VERSION ""

NS_ :

BS_:

BU_:

CM_ "FrameID: 0xC7";
BO_ 199 Toggle_Battery_Preconditioning: 8 Vector__XXX
 SG_ Battery_Preconditioning_0 : 24|8@1+ (1,0) [0|255] "" Vector__XXX
 SG_ Battery_Preconditioning_1 : 32|8@1+ (1,0) [0|255] "" Vector__XXX

CM_ "FrameID: 411";
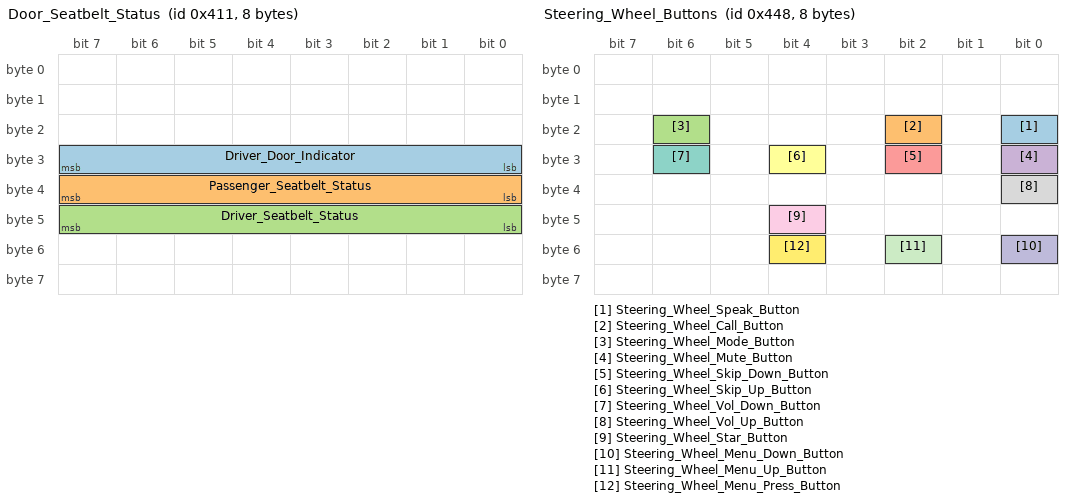
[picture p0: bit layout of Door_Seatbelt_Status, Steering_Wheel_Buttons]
BO_ 1041 Door_Seatbelt_Status: 8 Vector__XXX
 SG_ Driver_Door_Indicator      : 24|8@1+ (1,0) [0|255] "" Vector__XXX
 SG_ Passenger_Seatbelt_Status  : 32|8@1+ (1,0) [0|255] "" Vector__XXX
 SG_ Driver_Seatbelt_Status     : 40|8@1+ (1,0) [0|255] "" Vector__XXX

CM_ "FrameID: 412";
BO_ 1042 Brake_Pedal_Status: 8 Vector__XXX
 SG_ Brake_Pedal : 48|8@1+ (1,0) [0|255] "" Vector__XXX

CM_ "FrameID: 435";
BO_ 1077 Power_CAN_Status: 8 Vector__XXX
 SG_ Power_State : 56|8@1+ (1,0) [0|255] "" Vector__XXX

CM_ "FrameID: 0x2AD";
BO_ 685 BMS_Precond_Status: 8 Vector__XXX
 SG_ Battery_Precond_State : 8|8@1+ (1,0) [0|255] "" Vector__XXX

CM_ "FrameID: 0x418";
BO_ 1048 Steering_Wheel_Heating: 8 Vector__XXX
 SG_ Steering_Wheel_Heating_State : 16|8@1+ (1,0) [0|255] "" Vector__XXX

CM_ "FrameID: 0x438";
BO_ 1080 RearLeft_Seat_Heating: 8 Vector__XXX
 SG_ RearLeft_Seat_Heating_State :  0|8@1+ (1,0) [0|255] "" Vector__XXX

CM_ "FrameID: 0x448";
BO_ 1096 Steering_Wheel_Buttons: 8 Vector__XXX
 SG_ Steering_Wheel_Speak_Button      : 16|1@1+ (1,0) [0|1] "" Vector__XXX
 SG_ Steering_Wheel_Call_Button       : 18|1@1+ (1,0) [0|1] "" Vector__XXX
 SG_ Steering_Wheel_Mode_Button       : 22|1@1+ (1,0) [0|1] "" Vector__XXX
 SG_ Steering_Wheel_Mute_Button       : 24|1@1+ (1,0) [0|1] "" Vector__XXX
 SG_ Steering_Wheel_Skip_Down_Button  : 26|1@1+ (1,0) [0|1] "" Vector__XXX
 SG_ Steering_Wheel_Skip_Up_Button    : 28|1@1+ (1,0) [0|1] "" Vector__XXX
 SG_ Steering_Wheel_Vol_Down_Button   : 30|1@1+ (1,0) [0|1] "" Vector__XXX
 SG_ Steering_Wheel_Vol_Up_Button     : 32|1@1+ (1,0) [0|1] "" Vector__XXX
 SG_ Steering_Wheel_Star_Button       : 44|1@1+ (1,0) [0|1] "" Vector__XXX
 SG_ Steering_Wheel_Menu_Down_Button  : 48|1@1+ (1,0) [0|1] "" Vector__XXX
 SG_ Steering_Wheel_Menu_Up_Button    : 50|1@1+ (1,0) [0|1] "" Vector__XXX
 SG_ Steering_Wheel_Menu_Press_Button : 52|1@1+ (1,0) [0|1] "" Vector__XXX

CM_ "FrameID: 0x453";
BO_ 1107 RearRight_Seat_Heating: 8 Vector__XXX
 SG_ RearRight_Seat_Heating_State : 0|8@1+ (1,0) [0|255] "" Vector__XXX

CM_ "FrameID: 0x475";
BO_ 1141 Passenger_Seat_Heating: 8 Vector__XXX
 SG_ Passenger_Seat_Heating_State : 0|8@1+ (1,0) [0|255] "" Vector__XXX

CM_ "FrameID: 0x496";
BO_ 1174 Driver_Seat_Heating: 8 Vector__XXX
 SG_ Driver_Seat_Heating_State :    0|8@1+ (1,0) [0|255] "" Vector__XXX

CM_ "FrameID: 0x4ED";
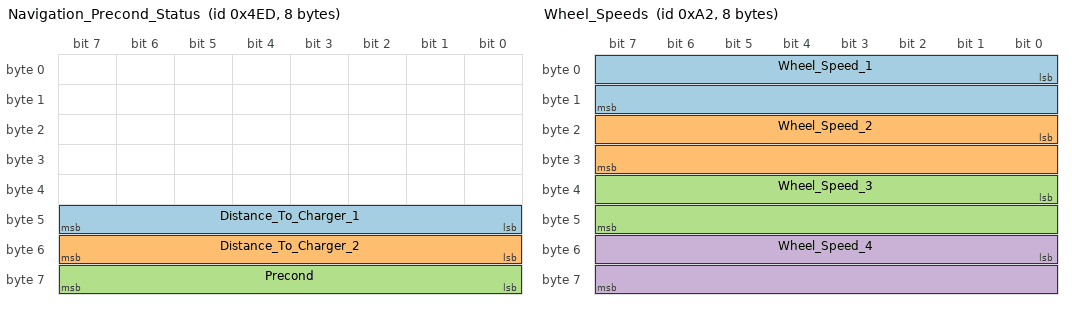
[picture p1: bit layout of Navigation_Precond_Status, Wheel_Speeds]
BO_ 1261 Navigation_Precond_Status: 8 Vector__XXX
 SG_ Distance_To_Charger_1 : 40|8@1+ (1,0) [0|255] "" Vector__XXX
 SG_ Distance_To_Charger_2 : 48|8@1+ (1,0) [0|255] "" Vector__XXX
 SG_ Precond               : 56|8@1+ (1,0) [0|255] "" Vector__XXX

CM_ "FrameID: 0x0A2";
BO_ 162 Wheel_Speeds: 8 Vector__XXX
 SG_ Wheel_Speed_1 : 0|16@1+  (0.03125,0) [0|2047.96] "kph" Vector__XXX
 SG_ Wheel_Speed_2 : 16|16@1+ (0.03125,0) [0|2047.96] "kph" Vector__XXX
 SG_ Wheel_Speed_3 : 32|16@1+ (0.03125,0) [0|2047.96] "kph" Vector__XXX
 SG_ Wheel_Speed_4 : 48|16@1+ (0.03125,0) [0|2047.96] "kph" Vector__XXX

CM_ "FrameID: 0x1AC";
BO_ 428 Cluster_Info: 8 Vector__XXX
 SG_ Speed_kph : 0|8@1+ (1,0) [0|255] "kph" Vector__XXX

CM_ "FrameID: 0x226";
CM_ "Probably wrong: unsigned int, and this byte doesn't change in my logs. --TRH"
BO_ 550 Ambient_Temperature: 8 Vector__XXX
 SG_ Outdoor_Temperature : 24|8@1+ (1,-40) [-40|215] "C" Vector__XXX

CM_ "FrameID: 0x227";
BO_ 551 Odometer: 8 Vector__XXX
 SG_ Odometer : 8|24@1+ (0.1,0) [0|1677721] "km" Vector__XXX

CM_ "FrameID: 0x2FC";
BO_ 764 Battery_Info: 8 Vector__XXX
 SG_ State_Of_Charge : 56|8@1+ (0.5,0) [0|100] "%" Vector__XXX

CM_ "FrameID: 0x31B";
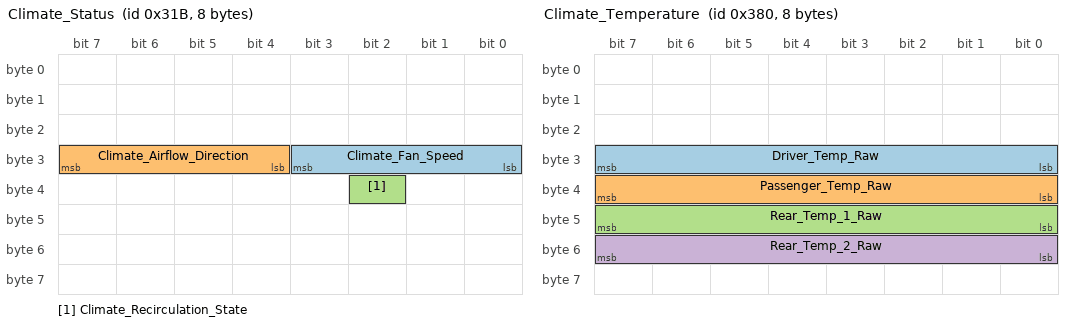
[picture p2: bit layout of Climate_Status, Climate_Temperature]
BO_ 795 Climate_Status: 8 Vector__XXX
 SG_ Climate_Fan_Speed          : 24|4@1+ (1,0) [0|15] "" Vector__XXX
 SG_ Climate_Airflow_Direction  : 28|4@1+ (1,0) [0|15] "" Vector__XXX
 SG_ Climate_Recirculation_State: 34|1@1+ (1,0) [0|1]  "" Vector__XXX

CM_ "FrameID: 0x380";
BO_ 896 Climate_Temperature: 8 Vector__XXX
 SG_ Driver_Temp_Raw    : 24|8@1+ (0.5,14) [14|32] "C" Vector__XXX
 SG_ Passenger_Temp_Raw : 32|8@1+ (0.5,14) [14|32] "C" Vector__XXX
 SG_ Rear_Temp_1_Raw    : 40|8@1+ (0.5,14) [14|32] "C" Vector__XXX
 SG_ Rear_Temp_2_Raw    : 48|8@1+ (0.5,14) [14|32] "C" Vector__XXX

CM_ "FrameID: 0x3AA";
BO_ 938 Charge_Port_Door: 8 Vector__XXX
 SG_ Port_Open : 33|1@1+ (1,0) [0|1] "" Vector__XXX

CM_ "FrameID: 0x414";
BO_ 1044 Trunk_Status: 8 Vector__XXX
 SG_ Trunk_Open : 24|1@1+ (1,0) [0|1] "" Vector__XXX

VAL_ 199  Battery_Preconditioning_0    64 "On" 0 "Off";
VAL_ 199  Battery_Preconditioning_1    3 "On" 0 "Off";
VAL_ 1041 Driver_Door_Indicator      51 "Open" 50 "Closed" 0 "Locked";
VAL_ 1041 Passenger_Seatbelt_Status  16 "Fastened" 0 "Unfastened";
VAL_ 1041 Driver_Seatbelt_Status      4 "Fastened" 0 "Unfastened";
VAL_ 1042 Brake_Pedal                 4 "Pressed" 0 "Not_Pressed";
VAL_ 1077 Power_State               255 "Car_Off" 0 "Car_on";
VAL_ 685  Battery_Precond_State        21 "On" 5 "Preparing" 1 "Off" ;
VAL_ 1080 RearLeft_Seat_Heating_State  65 "High" 49 "Low" 17 "Off" ;
VAL_ 1048 Steering_Wheel_Heating_State 1 "On" 0 "Off" ;
VAL_ 1096 Steering_Wheel_Speak_Button      1 "Pressed" 0 "Not_Pressed";
VAL_ 1096 Steering_Wheel_Call_Button       1 "Pressed" 0 "Not_Pressed";
VAL_ 1096 Steering_Wheel_Mode_Button       1 "Pressed" 0 "Not_Pressed";
VAL_ 1096 Steering_Wheel_Mute_Button       1 "Pressed" 0 "Not_Pressed";
VAL_ 1096 Steering_Wheel_Skip_Down_Button  1 "Pressed" 0 "Not_Pressed";
VAL_ 1096 Steering_Wheel_Skip_Up_Button    1 "Pressed" 0 "Not_Pressed";
VAL_ 1096 Steering_Wheel_Vol_Down_Button   1 "Pressed" 0 "Not_Pressed";
VAL_ 1096 Steering_Wheel_Vol_Up_Button     1 "Pressed" 0 "Not_Pressed";
VAL_ 1096 Steering_Wheel_Star_Button       1 "Pressed" 0 "Not_Pressed";
VAL_ 1096 Steering_Wheel_Menu_Down_Button  1 "Pressed" 0 "Not_Pressed";
VAL_ 1096 Steering_Wheel_Menu_Up_Button    1 "Pressed" 0 "Not_Pressed";
VAL_ 1096 Steering_Wheel_Menu_Press_Button 1 "Pressed" 0 "Not_Pressed";
VAL_ 1107 RearRight_Seat_Heating_State 65 "High" 49 "Low" 17 "Off" ;
VAL_ 1141 Passenger_Seat_Heating_State 70 "High" 62 "Medium" 54 "Low" 22 "Off" ;
VAL_ 1174 Driver_Seat_Heating_State    70 "High" 62 "Medium" 54 "Low" 22 "Off" ;
VAL_ 795 Climate_Fan_Speed 0 "Off" 2 "Speed_1" 3 "Speed_2" 4 "Speed_3" 5 "Speed_4" 6 "Speed_5" 7 "Speed_6" 8 "Speed_7" 9 "Speed_8" ;
VAL_ 795 Climate_Airflow_Direction 0 "Auto" 1 "Body" 2 "Body_Legs" 3 "Legs" 4 "Legs_Defog" ;
VAL_ 795 Climate_Recirculation_State 0 "Off" 1 "On" ;
VAL_ 896 Driver_Temp_Raw 0 "Off" ;
VAL_ 896 Passenger_Temp_Raw 0 "Off" ;
VAL_ 896 Rear_Temp_1_Raw 0 "Off" ;
VAL_ 896 Rear_Temp_2_Raw 0 "Off" ;

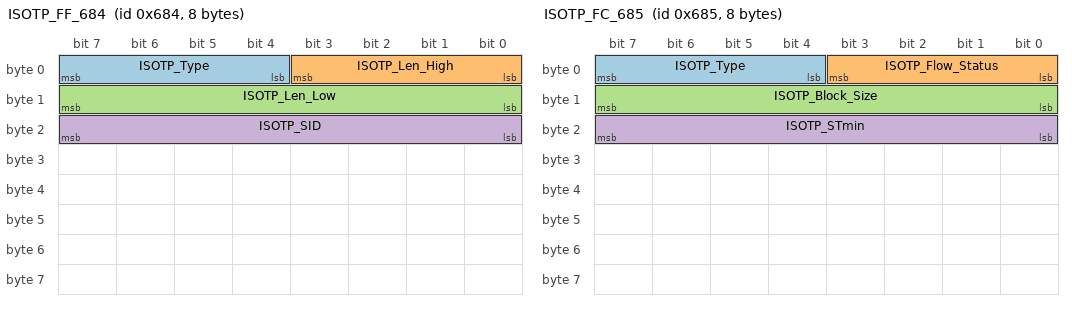
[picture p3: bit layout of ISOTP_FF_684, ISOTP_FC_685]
BO_ 1668 ISOTP_FF_684: 8 Vector__XXX
 SG_ ISOTP_Type        : 4|4@1+  (1,0) [0|15]  ""   Vector__XXX
 SG_ ISOTP_Len_High    : 0|4@1+  (1,0) [0|15]  ""   Vector__XXX
 SG_ ISOTP_Len_Low     : 8|8@1+  (1,0) [0|255] ""   Vector__XXX
 SG_ ISOTP_SID         : 16|8@1+ (1,0) [0|255] ""   Vector__XXX

CM_ BO_ 1668 "ISO-TP First Frame 0x684 → FC from 0x685. TotalLen=(Len_High<<8)|Len_Low";

BO_ 1669 ISOTP_FC_685: 8 Vector__XXX
 SG_ ISOTP_Type        : 4|4@1+  (1,0) [0|15]  ""   Vector__XXX
 SG_ ISOTP_Flow_Status : 0|4@1+  (1,0) [0|15]  ""   Vector__XXX
 SG_ ISOTP_Block_Size  : 8|8@1+  (1,0) [0|255] ""   Vector__XXX
 SG_ ISOTP_STmin       : 16|8@1+ (1,0) [0|255] "ms" Vector__XXX

CM_ BO_ 1669 "ISO-TP Flow Control 0x685 → responding to 0x684";

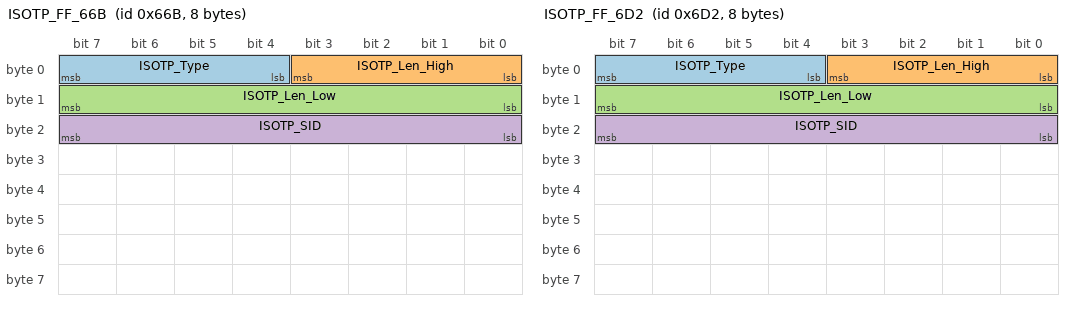
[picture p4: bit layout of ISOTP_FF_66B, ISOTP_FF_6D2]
BO_ 1643 ISOTP_FF_66B: 8 Vector__XXX
 SG_ ISOTP_Type        : 4|4@1+  (1,0) [0|15]  ""   Vector__XXX
 SG_ ISOTP_Len_High    : 0|4@1+  (1,0) [0|15]  ""   Vector__XXX
 SG_ ISOTP_Len_Low     : 8|8@1+  (1,0) [0|255] ""   Vector__XXX
 SG_ ISOTP_SID         : 16|8@1+ (1,0) [0|255] ""   Vector__XXX

CM_ BO_ 1643 "ISO-TP First Frame 0x66B → FC from 0x69B";

BO_ 1746 ISOTP_FF_6D2: 8 Vector__XXX
 SG_ ISOTP_Type        : 4|4@1+  (1,0) [0|15]  ""   Vector__XXX
 SG_ ISOTP_Len_High    : 0|4@1+  (1,0) [0|15]  ""   Vector__XXX
 SG_ ISOTP_Len_Low     : 8|8@1+  (1,0) [0|255] ""   Vector__XXX
 SG_ ISOTP_SID         : 16|8@1+ (1,0) [0|255] ""   Vector__XXX

CM_ BO_ 1746 "ISO-TP First Frame 0x6D2 → FC from 0x69B";

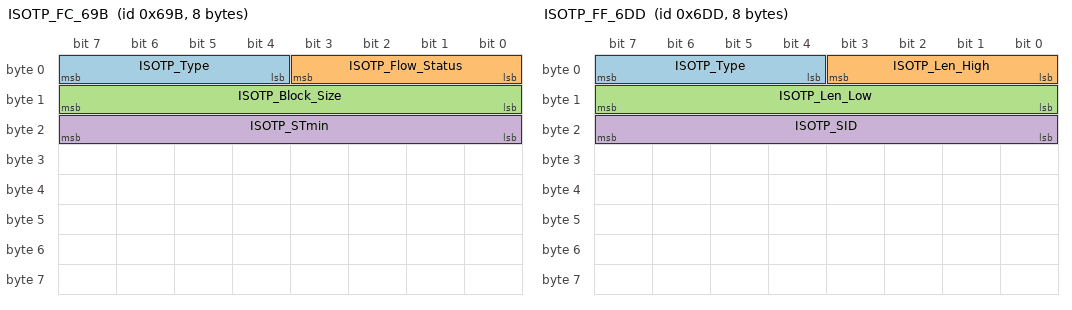
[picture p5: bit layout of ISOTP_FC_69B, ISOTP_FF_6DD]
BO_ 1691 ISOTP_FC_69B: 8 Vector__XXX
 SG_ ISOTP_Type        : 4|4@1+  (1,0) [0|15]  ""   Vector__XXX
 SG_ ISOTP_Flow_Status : 0|4@1+  (1,0) [0|15]  ""   Vector__XXX
 SG_ ISOTP_Block_Size  : 8|8@1+  (1,0) [0|255] ""   Vector__XXX
 SG_ ISOTP_STmin       : 16|8@1+ (1,0) [0|255] "ms" Vector__XXX

CM_ BO_ 1691 "ISO-TP Flow Control 0x69B → responding to 0x66B and 0x6D2";

BO_ 1757 ISOTP_FF_6DD: 8 Vector__XXX
 SG_ ISOTP_Type        : 4|4@1+  (1,0) [0|15]  ""   Vector__XXX
 SG_ ISOTP_Len_High    : 0|4@1+  (1,0) [0|15]  ""   Vector__XXX
 SG_ ISOTP_Len_Low     : 8|8@1+  (1,0) [0|255] ""   Vector__XXX
 SG_ ISOTP_SID         : 16|8@1+ (1,0) [0|255] ""   Vector__XXX

CM_ BO_ 1757 "ISO-TP First Frame 0x6DD → FC from 0x69E";

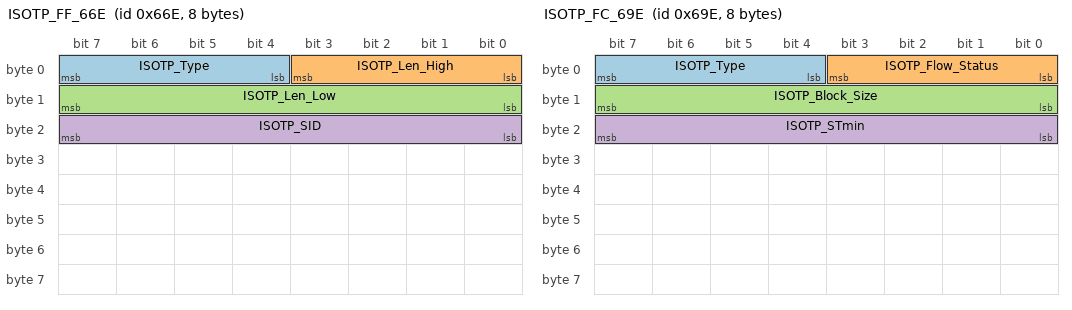
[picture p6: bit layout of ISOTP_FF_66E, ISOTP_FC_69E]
BO_ 1646 ISOTP_FF_66E: 8 Vector__XXX
 SG_ ISOTP_Type        : 4|4@1+  (1,0) [0|15]  ""   Vector__XXX
 SG_ ISOTP_Len_High    : 0|4@1+  (1,0) [0|15]  ""   Vector__XXX
 SG_ ISOTP_Len_Low     : 8|8@1+  (1,0) [0|255] ""   Vector__XXX
 SG_ ISOTP_SID         : 16|8@1+ (1,0) [0|255] ""   Vector__XXX

CM_ BO_ 1646 "ISO-TP First Frame 0x66E → FC from 0x69E";

BO_ 1694 ISOTP_FC_69E: 8 Vector__XXX
 SG_ ISOTP_Type        : 4|4@1+  (1,0) [0|15]  ""   Vector__XXX
 SG_ ISOTP_Flow_Status : 0|4@1+  (1,0) [0|15]  ""   Vector__XXX
 SG_ ISOTP_Block_Size  : 8|8@1+  (1,0) [0|255] ""   Vector__XXX
 SG_ ISOTP_STmin       : 16|8@1+ (1,0) [0|255] "ms" Vector__XXX

CM_ BO_ 1694 "ISO-TP Flow Control 0x69E → responding to 0x6DD and 0x66E";

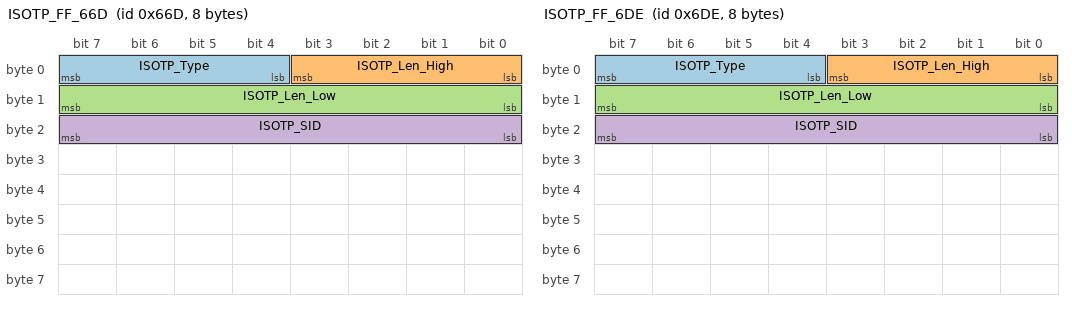
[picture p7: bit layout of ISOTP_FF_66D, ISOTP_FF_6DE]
BO_ 1645 ISOTP_FF_66D: 8 Vector__XXX
 SG_ ISOTP_Type        : 4|4@1+  (1,0) [0|15]  ""   Vector__XXX
 SG_ ISOTP_Len_High    : 0|4@1+  (1,0) [0|15]  ""   Vector__XXX
 SG_ ISOTP_Len_Low     : 8|8@1+  (1,0) [0|255] ""   Vector__XXX
 SG_ ISOTP_SID         : 16|8@1+ (1,0) [0|255] ""   Vector__XXX

CM_ BO_ 1645 "ISO-TP First Frame 0x66D → FC from 0x69D";

BO_ 1758 ISOTP_FF_6DE: 8 Vector__XXX
 SG_ ISOTP_Type        : 4|4@1+  (1,0) [0|15]  ""   Vector__XXX
 SG_ ISOTP_Len_High    : 0|4@1+  (1,0) [0|15]  ""   Vector__XXX
 SG_ ISOTP_Len_Low     : 8|8@1+  (1,0) [0|255] ""   Vector__XXX
 SG_ ISOTP_SID         : 16|8@1+ (1,0) [0|255] ""   Vector__XXX

CM_ BO_ 1758 "ISO-TP First Frame 0x6DE → FC from 0x69D";

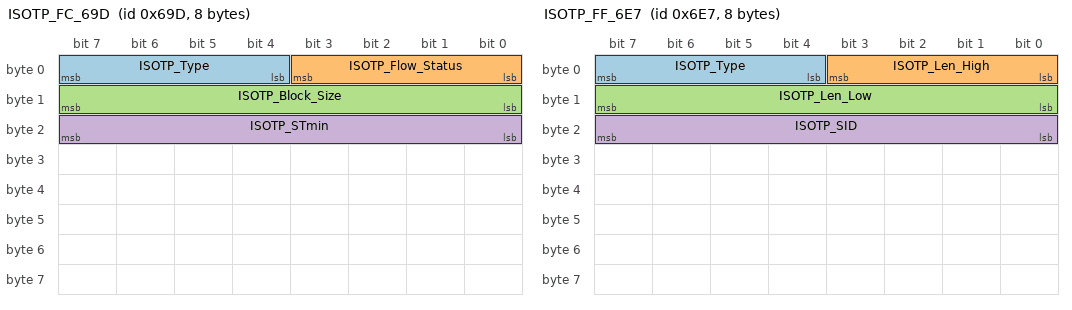
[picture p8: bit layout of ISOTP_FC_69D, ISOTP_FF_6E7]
BO_ 1693 ISOTP_FC_69D: 8 Vector__XXX
 SG_ ISOTP_Type        : 4|4@1+  (1,0) [0|15]  ""   Vector__XXX
 SG_ ISOTP_Flow_Status : 0|4@1+  (1,0) [0|15]  ""   Vector__XXX
 SG_ ISOTP_Block_Size  : 8|8@1+  (1,0) [0|255] ""   Vector__XXX
 SG_ ISOTP_STmin       : 16|8@1+ (1,0) [0|255] "ms" Vector__XXX

CM_ BO_ 1693 "ISO-TP Flow Control 0x69D → responding to 0x66D and 0x6DE";

BO_ 1767 ISOTP_FF_6E7: 8 Vector__XXX
 SG_ ISOTP_Type        : 4|4@1+  (1,0) [0|15]  ""   Vector__XXX
 SG_ ISOTP_Len_High    : 0|4@1+  (1,0) [0|15]  ""   Vector__XXX
 SG_ ISOTP_Len_Low     : 8|8@1+  (1,0) [0|255] ""   Vector__XXX
 SG_ ISOTP_SID         : 16|8@1+ (1,0) [0|255] ""   Vector__XXX

CM_ BO_ 1767 "ISO-TP First Frame 0x6E7 → FC from 0x6F4";

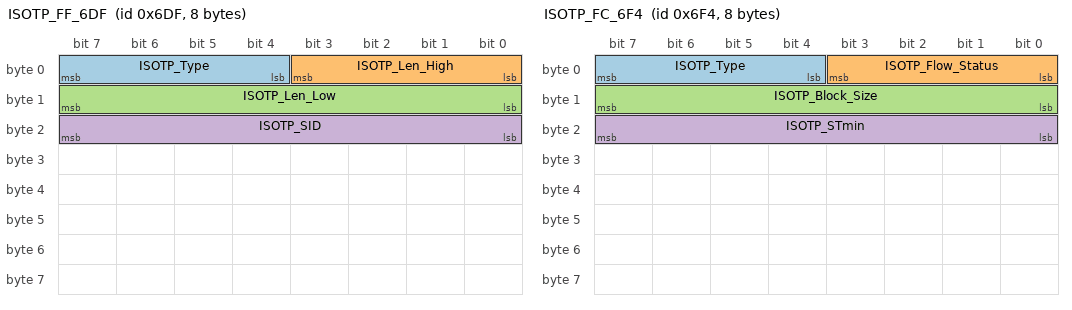
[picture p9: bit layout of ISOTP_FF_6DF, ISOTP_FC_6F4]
BO_ 1759 ISOTP_FF_6DF: 8 Vector__XXX
 SG_ ISOTP_Type        : 4|4@1+  (1,0) [0|15]  ""   Vector__XXX
 SG_ ISOTP_Len_High    : 0|4@1+  (1,0) [0|15]  ""   Vector__XXX
 SG_ ISOTP_Len_Low     : 8|8@1+  (1,0) [0|255] ""   Vector__XXX
 SG_ ISOTP_SID         : 16|8@1+ (1,0) [0|255] ""   Vector__XXX

CM_ BO_ 1759 "ISO-TP First Frame 0x6DF → FC from 0x6F4";

BO_ 1780 ISOTP_FC_6F4: 8 Vector__XXX
 SG_ ISOTP_Type        : 4|4@1+  (1,0) [0|15]  ""   Vector__XXX
 SG_ ISOTP_Flow_Status : 0|4@1+  (1,0) [0|15]  ""   Vector__XXX
 SG_ ISOTP_Block_Size  : 8|8@1+  (1,0) [0|255] ""   Vector__XXX
 SG_ ISOTP_STmin       : 16|8@1+ (1,0) [0|255] "ms" Vector__XXX

CM_ BO_ 1780 "ISO-TP Flow Control 0x6F4 → responding to 0x6E7 and 0x6DF";

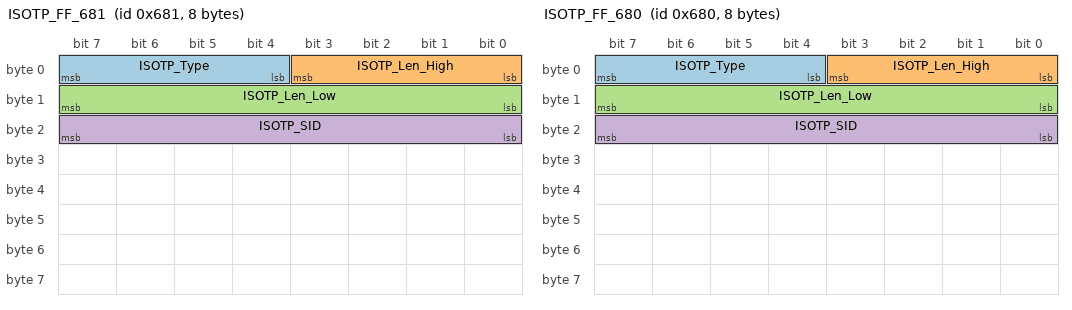
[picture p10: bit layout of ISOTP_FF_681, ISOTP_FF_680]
BO_ 1665 ISOTP_FF_681: 8 Vector__XXX
 SG_ ISOTP_Type        : 4|4@1+  (1,0) [0|15]  ""   Vector__XXX
 SG_ ISOTP_Len_High    : 0|4@1+  (1,0) [0|15]  ""   Vector__XXX
 SG_ ISOTP_Len_Low     : 8|8@1+  (1,0) [0|255] ""   Vector__XXX
 SG_ ISOTP_SID         : 16|8@1+ (1,0) [0|255] ""   Vector__XXX

CM_ BO_ 1665 "ISO-TP First Frame 0x681 → FC from 0x6AA";

BO_ 1664 ISOTP_FF_680: 8 Vector__XXX
 SG_ ISOTP_Type        : 4|4@1+  (1,0) [0|15]  ""   Vector__XXX
 SG_ ISOTP_Len_High    : 0|4@1+  (1,0) [0|15]  ""   Vector__XXX
 SG_ ISOTP_Len_Low     : 8|8@1+  (1,0) [0|255] ""   Vector__XXX
 SG_ ISOTP_SID         : 16|8@1+ (1,0) [0|255] ""   Vector__XXX

CM_ BO_ 1664 "ISO-TP First Frame 0x680 → FC from 0x6AA";

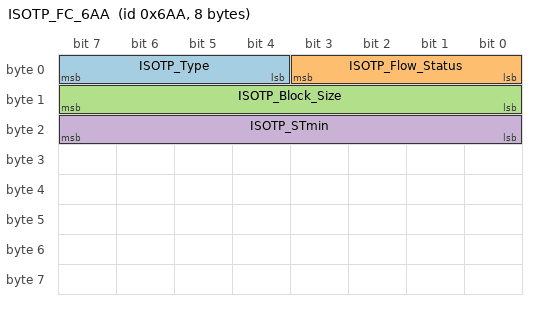
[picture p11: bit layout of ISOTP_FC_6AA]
BO_ 1706 ISOTP_FC_6AA: 8 Vector__XXX
 SG_ ISOTP_Type        : 4|4@1+  (1,0) [0|15]  ""   Vector__XXX
 SG_ ISOTP_Flow_Status : 0|4@1+  (1,0) [0|15]  ""   Vector__XXX
 SG_ ISOTP_Block_Size  : 8|8@1+  (1,0) [0|255] ""   Vector__XXX
 SG_ ISOTP_STmin       : 16|8@1+ (1,0) [0|255] "ms" Vector__XXX

CM_ BO_ 1706 "ISO-TP Flow Control 0x6AA → responding to 0x680 and 0x681";

VAL_ 1668 ISOTP_Type 0 "SingleFrame" 1 "FirstFrame" 2 "ConsecFrame" 3 "FlowCtrl";
VAL_ 1643 ISOTP_Type 0 "SingleFrame" 1 "FirstFrame" 2 "ConsecFrame" 3 "FlowCtrl";
VAL_ 1746 ISOTP_Type 0 "SingleFrame" 1 "FirstFrame" 2 "ConsecFrame" 3 "FlowCtrl";
VAL_ 1757 ISOTP_Type 0 "SingleFrame" 1 "FirstFrame" 2 "ConsecFrame" 3 "FlowCtrl";
VAL_ 1646 ISOTP_Type 0 "SingleFrame" 1 "FirstFrame" 2 "ConsecFrame" 3 "FlowCtrl";
VAL_ 1645 ISOTP_Type 0 "SingleFrame" 1 "FirstFrame" 2 "ConsecFrame" 3 "FlowCtrl";
VAL_ 1758 ISOTP_Type 0 "SingleFrame" 1 "FirstFrame" 2 "ConsecFrame" 3 "FlowCtrl";
VAL_ 1767 ISOTP_Type 0 "SingleFrame" 1 "FirstFrame" 2 "ConsecFrame" 3 "FlowCtrl";
VAL_ 1759 ISOTP_Type 0 "SingleFrame" 1 "FirstFrame" 2 "ConsecFrame" 3 "FlowCtrl";
VAL_ 1665 ISOTP_Type 0 "SingleFrame" 1 "FirstFrame" 2 "ConsecFrame" 3 "FlowCtrl";
VAL_ 1664 ISOTP_Type 0 "SingleFrame" 1 "FirstFrame" 2 "ConsecFrame" 3 "FlowCtrl";
VAL_ 1669 ISOTP_Type 0 "SingleFrame" 1 "FirstFrame" 2 "ConsecFrame" 3 "FlowCtrl";
VAL_ 1691 ISOTP_Type 0 "SingleFrame" 1 "FirstFrame" 2 "ConsecFrame" 3 "FlowCtrl";
VAL_ 1694 ISOTP_Type 0 "SingleFrame" 1 "FirstFrame" 2 "ConsecFrame" 3 "FlowCtrl";
VAL_ 1693 ISOTP_Type 0 "SingleFrame" 1 "FirstFrame" 2 "ConsecFrame" 3 "FlowCtrl";
VAL_ 1780 ISOTP_Type 0 "SingleFrame" 1 "FirstFrame" 2 "ConsecFrame" 3 "FlowCtrl";
VAL_ 1706 ISOTP_Type 0 "SingleFrame" 1 "FirstFrame" 2 "ConsecFrame" 3 "FlowCtrl";
VAL_ 1669 ISOTP_Flow_Status 0 "ContinueToSend" 1 "Wait" 2 "Overflow";
VAL_ 1691 ISOTP_Flow_Status 0 "ContinueToSend" 1 "Wait" 2 "Overflow";
VAL_ 1694 ISOTP_Flow_Status 0 "ContinueToSend" 1 "Wait" 2 "Overflow";
VAL_ 1693 ISOTP_Flow_Status 0 "ContinueToSend" 1 "Wait" 2 "Overflow";
VAL_ 1780 ISOTP_Flow_Status 0 "ContinueToSend" 1 "Wait" 2 "Overflow";
VAL_ 1706 ISOTP_Flow_Status 0 "ContinueToSend" 1 "Wait" 2 "Overflow";

BO_ 996 VIN_Broadcast: 8 Vector__XXX
 SG_ VIN_Frame M  :  0|8@1+ (1,0) [0|255] "" Vector__XXX
 SG_ VIN_C01 m42  : 56|8@1+ (1,0) [0|255] "" Vector__XXX
 SG_ VIN_C02 m42  : 48|8@1+ (1,0) [0|255] "" Vector__XXX
 SG_ VIN_C03 m42  : 40|8@1+ (1,0) [0|255] "" Vector__XXX
 SG_ VIN_C04 m42  : 32|8@1+ (1,0) [0|255] "" Vector__XXX
 SG_ VIN_C05 m42  : 24|8@1+ (1,0) [0|255] "" Vector__XXX
 SG_ VIN_C06 m42  : 16|8@1+ (1,0) [0|255] "" Vector__XXX
 SG_ VIN_C07 m42  :  8|8@1+ (1,0) [0|255] "" Vector__XXX
 SG_ VIN_C08 m74  : 56|8@1+ (1,0) [0|255] "" Vector__XXX
 SG_ VIN_C09 m74  : 48|8@1+ (1,0) [0|255] "" Vector__XXX
 SG_ VIN_C10 m74  : 40|8@1+ (1,0) [0|255] "" Vector__XXX
 SG_ VIN_C11 m74  : 32|8@1+ (1,0) [0|255] "" Vector__XXX
 SG_ VIN_C12 m74  : 24|8@1+ (1,0) [0|255] "" Vector__XXX
 SG_ VIN_C13 m74  : 16|8@1+ (1,0) [0|255] "" Vector__XXX
 SG_ VIN_C14 m74  :  8|8@1+ (1,0) [0|255] "" Vector__XXX
 SG_ VIN_C15 m106 : 56|8@1+ (1,0) [0|255] "" Vector__XXX
 SG_ VIN_C16 m106 : 48|8@1+ (1,0) [0|255] "" Vector__XXX
 SG_ VIN_C17 m106 : 40|8@1+ (1,0) [0|255] "" Vector__XXX

CM_ BO_ 996 "VIN broadcast 0x3E4. Byte 0 = frame counter. VIN chars stored in reverse byte order (byte7=VIN[1], byte6=VIN[2]...). Frame 0x2A: VIN[1-7]=KMHKR81, Frame 0x4A: VIN[8-14]=CPNU058, Frame 0x6A: VIN[15-17]=627";

VAL_ 996 VIN_Frame 42 "VIN_chars_01_07" 74 "VIN_chars_08_14" 106 "VIN_chars_15_17";
